# DSS_DSS_VIDL1_30202000h register map
Vendor: Texas Instruments
Peripheral module from a debugger description file (folder am62L).
Registers are 32-bit, read-write, reset 0x0 unless marked. A register's access mark holds for its fields unless they carry their own. Offsets are as the file gives them; lines under a group give offsets from that group; [hi:lo] are bit positions; {n}, {i} and the like mark numbered series; 'fields as' and 'values as' point back to an identical list; <NAME> marks a mode.

## DSS_VIDL1
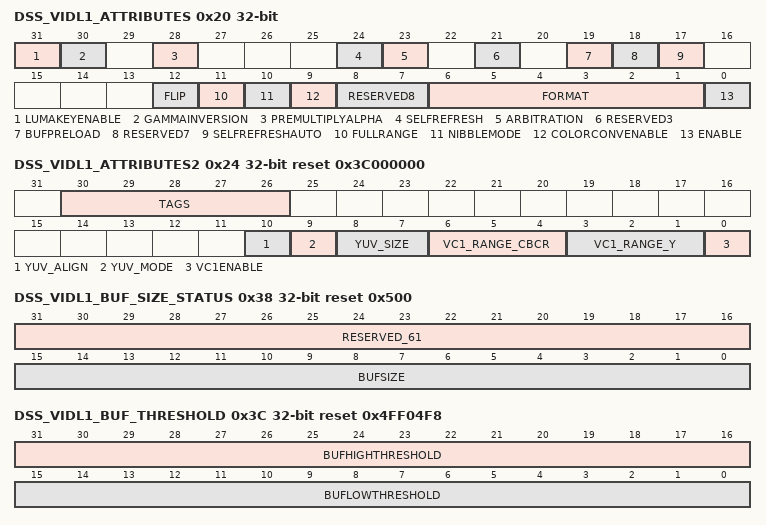
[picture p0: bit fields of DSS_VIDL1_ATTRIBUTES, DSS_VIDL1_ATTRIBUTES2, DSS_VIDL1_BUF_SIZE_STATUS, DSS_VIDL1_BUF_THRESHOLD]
0x20 DSS_VIDL1_ATTRIBUTES access per field — The register configures the attributes of the video window. Shadow register
  [31] LUMAKEYENABLE rw — Enable Luma Key transparency matching 0 Luma Key operation is disabled1 Luma Key operation is enabled
  [30] GAMMAINVERSION rw — Inverse Gamma support [using the CLUT table] 0 Gamma inversion is disabled1 Gamma inversion is enabled
  [28] PREMULTIPLYALPHA rw — The field configures the DISPC VID to process incoming data as premultiplied alpha data or non premultiplied alpha data. Default setting is non premultiplied alpha data 0 Non premultiplyalpha data color component1 Premultiplyalpha data color component
  [24] SELFREFRESH rw — Enables the self refresh of the video window, from its own DMA buffer only 0 The video pipeline accesses the interconnect to fetch data from the system memory1 The video pipeline does not need any more to fetch data from memory. Only the DMA buffer associated with the video1 is used. It takes effect after the frame has been loaded in the DMA buffer
  [23] ARBITRATION rw — Determines the priority of the video pipeline. The video pipeline is one of the high priority pipelines. The arbitration gives always the priority first to the high priority pipelines using round-robin between them. When there are only normal priority pipelines sending requests, the round-robin applies between the normal priority pipelines 0 The video pipeline is one of the normal priority pipelines1 The video pipeline is one of the high priority pipelines
  [21] RESERVED3 ro — Write 0's for future compatibility. Reads return 0
  [19] BUFPRELOAD rw — Video Preload Value 0 H/W prefetches pixels up to the preload value defined in the preload register1 H/W prefetches pixels up to high threshold value
  [18] RESERVED7 ro — Write 0's for future compatibility. Reads return 0
  [17] SELFREFRESHAUTO rw — Automatic self refresh mode 0 The transition from SELFREFRESH disabled to enabled is controlled SW1 The transition from SELFREFRESH disabled to enabled is controlled only by HW
  [12] FLIP rw — Describes the frame buffer flip operation 0 No Flip1 Frame Buffer is flipped
  [11] FULLRANGE rw — Color Space Conversion full range setting 0 Limited Range Selected1 Full Range Selected
  [10] NIBBLEMODE rw — Video Nibble mode [only for 1-, 2- and 4-bpp] 0 Nibble Mode Disabled1 Nibble Mode Enabled
  [9] COLORCONVENABLE rw — Enable the color space conversion. The HW does not enable/disable the conversion based on the pixel format 0 Color Space Conversion Disabled1 Color Space Conversion Enabled
  [8:7] RESERVED8 ro — Write 0's for future compatibility. Reads return 0
  [6:1] FORMAT rw — Video Format. It defines the pixel format when fetching the video frame buffer 0 Pixel format1 Pixel format2 Pixel format3 Pixel format4 Pixel format5 Pixel format6 Pixel format7 Pixel format8 Pixel format9 Pixel format10 Pixel format11 Pixel format12 Pixel format14 Pixel format15 Pixel format16 Pixel format17 Pixel format18 Pixel format19 Pixel format20 Pixel format21 Pixel format22 Pixel format23 Pixel format32 Pixel format33 Pixel format34 Pixel format37 Pixel format38 Pixel format39 Pixel format40 Pixel format41 Pixel format42 Pixel format46 Pixel format47 Pixel format48 Pixel format49 Pixel format61 Pixel format62 Pixel format63 Pixel format
  [0] ENABLE rw — Video pipeline Enable 0 Video Pipe Disabled1 Video Pipe Enabled
0x24 DSS_VIDL1_ATTRIBUTES2 reset 0x3C000000 — The register configures the attributes of the video window. Shadow register
  [30:26] TAGS — Number of OCP TAGS to be used for the pipeline [from 0x0 to 0xF]. A value of 0x0 means only a single tag will be used. A value of 0xF means all 16 tags can be used
  [10] YUV_ALIGN — Alignment [MSB or LSB align] for unpacked 10b/12b YUV data 0 lsb aligned - unused msb1 msb aligned - unused lsb
  [9] YUV_MODE — Mode of packing for YUV data [only for 10b/12b formats] 0 YUV 10-bit formats have the same component packing order as 8-bit formats except that the packing is done across a multiple 32-bit word with 2 MSB in each 32-bit word not used. YUV 12-bit formats have the same component packing order as 8-bit formats except that the packing is done across a multiple 64-bit word with 4 MSB in each 64-bit word not used1 YUV 10-bit/12-bit unpacked formats have the same component packing order as 8-bit formats except that each component is stored in a 16-bit container - with MSB or LSB bits within the 16-bit container not used depending on the MSB/LSB alignment
  [8:7] YUV_SIZE — Size of YUV data 8b/10b/12b 0 8b per component-default1 10b per component2 12b per component
  [6:4] VC1_RANGE_CBCR — Defines the VC1 range value for the CbCr component from 0 to 7
  [3:1] VC1_RANGE_Y — Defines the VC1 range value for the Y component from 0 to 7
  [0] VC1ENABLE — Enable/disable the VC1 range mapping processing. The bit-field is ignored if the format is not one of the supported YUV formats 0 VC1 range mapping disabled1 VC1 range mapping enabled
0x28 DSS_VIDL1_BA_0 — The register configures the base address of the single video buffer. In case of single plane ARGB or YUV, this is the BA. In case of two plane YUV, this is the BA_Y. In case of two plane RGB565-A8, this is the BA_Alpha. BA__0 & BA__1 for ping-pong mechanism with external trigger, based on the field polarity otherwise only BA__0 is used. Shadow register
  [31:0] BA — Video base address. Base address of the video buffer [Aligned on pixel size boundary except for the following. In case of RGB24 packed format, 4-pixel alignment is required. In case of YUV422, 2-pixel alignment is required. In case of YUV420, byte alignment is required]
0x2C DSS_VIDL1_BA_1 — The register configures the base address of the single video buffer. In case of single plane ARGB or YUV, this is the BA. In case of two plane YUV, this is the BA_Y. In case of two plane RGB565-A8, this is the BA_Alpha. BA__0 & BA__1 for ping-pong mechanism with external trigger, based on the field polarity otherwise only BA__0 is used. Shadow register
  fields as DSS_VIDL1_BA_0
0x30 DSS_VIDL1_BA_UV_0 — The register configures the base address of the UV buffer for two plane YUV or RGB buffer for two plane RGB565-A8, for the video window. BA_UV__0 & BA_UV__1 for ping-pong mechanism with external trigger, based on the field polarity otherwise only BA_UV__0 is used. Shadow register
  [31:0] BA — Video base address aligned on 16-bit boundary Base address of the UV video buffer used only in case of YUV420-NV12
0x34 DSS_VIDL1_BA_UV_1 — The register configures the base address of the UV buffer for two plane YUV or RGB buffer for two plane RGB565-A8, for the video window. BA_UV__0 & BA_UV__1 for ping-pong mechanism with external trigger, based on the field polarity otherwise only BA_UV__0 is used. Shadow register
  fields as DSS_VIDL1_BA_UV_0
0x38 DSS_VIDL1_BUF_SIZE_STATUS ro reset 0x500 — The register returns the Video buffer size for the video pipeline
  [31:16] RESERVED_61 — Write 0's for future compatibility Reads return 0
  [15:0] BUFSIZE — Video DMA buffer Size in number of 128-bits
0x3C DSS_VIDL1_BUF_THRESHOLD reset 0x4FF04F8 — The register configures the video buffer associated with the video pipeline. Shadow register
  [31:16] BUFHIGHTHRESHOLD — DMA buffer High Threshold. Number of 128-bits defining the threshold value
  [15:0] BUFLOWTHRESHOLD — DMA buffer Low Threshold. Number of 128-bits defining the threshold value
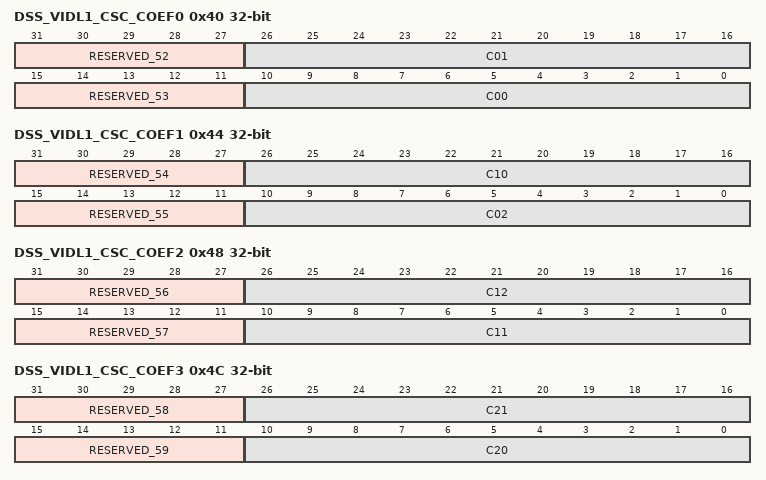
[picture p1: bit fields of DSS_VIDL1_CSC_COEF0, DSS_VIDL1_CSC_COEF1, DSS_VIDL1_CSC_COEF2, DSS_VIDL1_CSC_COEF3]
0x40 DSS_VIDL1_CSC_COEF0 access per field — The register configures the color space conversion matrix coefficients. Shadow register
  [31:27] RESERVED_52 ro — Write 0's for future compatibility Reads return 0
  [26:16] C01 rw — C01 Coefficient. Encoded signed value [from -1024 to 1023]
  [15:11] RESERVED_53 ro — Write 0's for future compatibility Reads return 0
  [10:0] C00 rw — C00 Coefficient. Encoded signed value [from -1024 to 1023]
0x44 DSS_VIDL1_CSC_COEF1 access per field — The register configures the color space conversion matrix coefficients. Shadow register
  [31:27] RESERVED_54 ro — Write 0's for future compatibility Reads return 0
  [26:16] C10 rw — C10 Coefficient. Encoded signed value [from -1024 to 1023]
  [15:11] RESERVED_55 ro — Write 0's for future compatibility Reads return 0
  [10:0] C02 rw — C02 Coefficient. Encoded signed value [from -1024 to 1023]
0x48 DSS_VIDL1_CSC_COEF2 access per field — The register configures the color space conversion matrix coefficients. Shadow register
  [31:27] RESERVED_56 ro — Write 0's for future compatibility Reads return 0
  [26:16] C12 rw — C12 Coefficient. Encoded signed value [from -1024 to 1023]
  [15:11] RESERVED_57 ro — Write 0's for future compatibility Reads return 0
  [10:0] C11 rw — C11 Coefficient. Encoded signed value [from -1024 to 1023]
0x4C DSS_VIDL1_CSC_COEF3 access per field — The register configures the color space conversion matrix coefficients. Shadow register
  [31:27] RESERVED_58 ro — Write 0's for future compatibility Reads return 0
  [26:16] C21 rw — C21 coefficient. Encoded signed value [from -1024 to 1023]
  [15:11] RESERVED_59 ro — Write 0's for future compatibility Reads return 0
  [10:0] C20 rw — C20 coefficient. Encoded signed value [from -1024 to 1023]
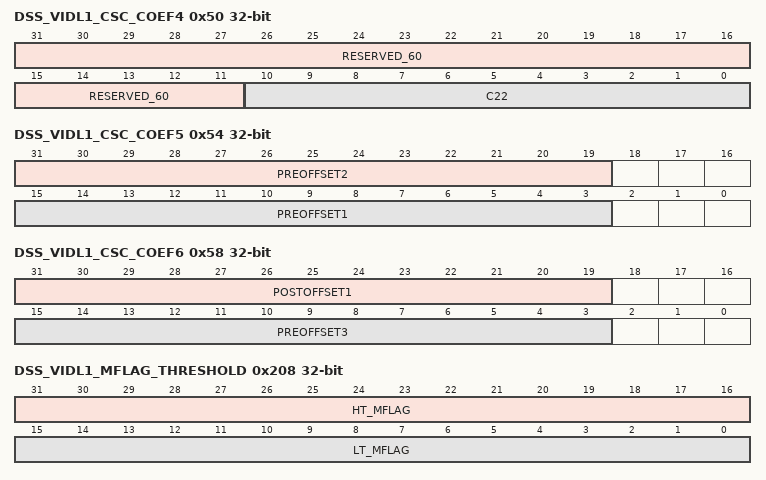
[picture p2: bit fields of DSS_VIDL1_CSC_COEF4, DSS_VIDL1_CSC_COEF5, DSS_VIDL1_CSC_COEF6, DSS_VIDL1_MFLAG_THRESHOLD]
0x50 DSS_VIDL1_CSC_COEF4 access per field — The register configures the color space conversion matrix coefficients. Shadow register
  [31:11] RESERVED_60 ro — Write 0's for future compatibility Reads return 0
  [10:0] C22 rw — C22 Coefficient. Encoded signed value [from -1024 to 1023]
0x54 DSS_VIDL1_CSC_COEF5 — The register configures the color space conversion matrix coefficients. Shadow register
  [31:19] PREOFFSET2 — Row-2 pre-offset. Encoded signed value [from -4096 to 4095]
  [15:3] PREOFFSET1 — Row1 pre-offset. Encoded signed value [from -4096 to 4095]
0x58 DSS_VIDL1_CSC_COEF6 — The register configures the color space conversion matrix coefficients. Shadow register
  [31:19] POSTOFFSET1 — Row-1 post-offset. Encoded signed value [from -4096 to 4095]
  [15:3] PREOFFSET3 — Row-3 pre-offset. Encoded signed value [from -4096 to 4095]
0x1FC DSS_VIDL1_GLOBAL_ALPHA reset 0xFF — The register defines the global alpha value for the video pipeline. Shadow register
  [7:0] GLOBALALPHA — Global alpha value from 0 to 255. 0 corresponds to fully transparent and 255 corresponds to fully opaque
0x208 DSS_VIDL1_MFLAG_THRESHOLD — MFLAG_THRESHOLD Register
  [31:16] HT_MFLAG — MFLAG High Threshold
  [15:0] LT_MFLAG — MFLAG Low Threshold
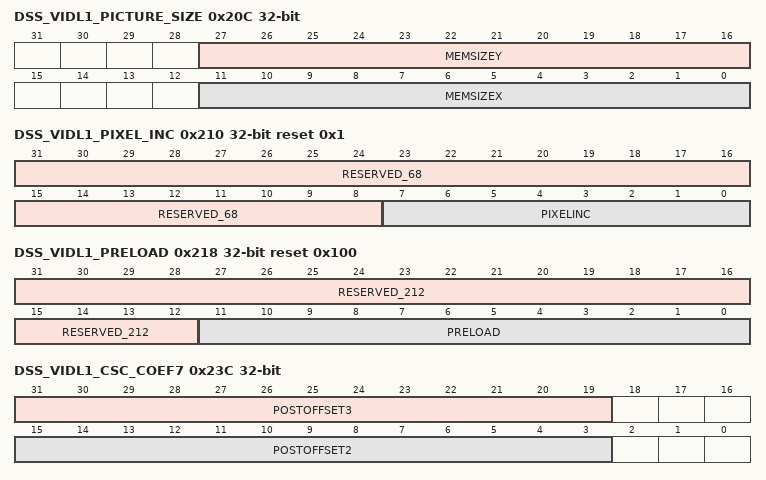
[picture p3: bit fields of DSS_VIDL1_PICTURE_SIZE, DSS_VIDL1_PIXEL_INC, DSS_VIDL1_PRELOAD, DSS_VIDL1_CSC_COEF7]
0x20C DSS_VIDL1_PICTURE_SIZE — The register configures the size of the video picture associated with the video layer before up/down-scaling. Shadow register
  [27:16] MEMSIZEY — Number of lines of the video picture Encoded value [from 1 to 4096] to specify the number of lines of the video picture in memory [program to value minus one]. When predecimation is set, the value represents the size of the image after predecimation but the max size of the unpredecimated image size in memory is still bounded to 2exp[11]
  [11:0] MEMSIZEX — Number of pixels of the video picture Encoded value [from 1 to 4096] to specify the number of pixels of the video picture in memory [program to value minus one]. The size is limited to the size of the line buffer of the vertical sampling block in case the video picture is processed by the vertical filtering unit [program to value minus one]. When predecimation is set, the value represents the size of the image after predecimation but the max size of the unpredecimated image size in memory is still bounded to 2exp[11]
0x210 DSS_VIDL1_PIXEL_INC access per field reset 0x1 — The register configures the number of bytes to increment between two pixels for the buffer associated with the video window. Shadow register
  [31:8] RESERVED_68 ro — Write 0's for future compatibility Reads return 0
  [7:0] PIXELINC rw — Number of bytes to increment between two pixels Encoded unsigned value [from 1 to 255] to specify the number of bytes between two pixels in the video buffer. The value 0 is invalid The value 1 means next pixel The value 1+n*bpp means increment of n pixels For YUV420. Max supported value is 128
0x218 DSS_VIDL1_PRELOAD access per field reset 0x100 — The register configures the DMA buffer of the video pipeline. Shadow register
  [31:12] RESERVED_212 ro — Write 0's for future compatibility Reads return 0
  [11:0] PRELOAD rw — DMA buffer preload value. Number of 128-bit words defining the preload value
0x21C DSS_VIDL1_ROW_INC reset 0x1 — The register configures the number of bytes to increment at the end of the row for the buffer associated with the video window. For YUV420 formats this corresponds to the Y Buffer. Shadow register
  [31:0] ROWINC — Number of bytes to increment at the end of the row Encoded signed value [from -2^31-1 to 2^31] to specify the number of bytes to increment at the end of the row in the video buffer. The value 0 is invalid. The value 1 means next pixel. The value 1+n*bpp means increment of n pixels The value 1- [n+1]*bpp means decrement of n pixels
0x22C DSS_VIDL1_BA_EXT_0 — The register configures the 16-bit base address extension. It is the base-address of the single video buffer for single plane ARGB or YUV. For the Y buffer for two plane YUV. For the Alpha buffer for two plane RGB565-A8. 0 & 1 : For ping-pong mechanism with external trigger, based on the field polarity. Shadow register
  [15:0] BA_EXT — Video base address extension [16 bits]. Addr extension to make the address space 48b wide
0x230 DSS_VIDL1_BA_EXT_1 — The register configures the 16-bit base address extension. It is the base-address of the single video buffer for single plane ARGB or YUV. For the Y buffer for two plane YUV. For the Alpha buffer for two plane RGB565-A8. 0 & 1 : For ping-pong mechanism with external trigger, based on the field polarity. Shadow register
  fields as DSS_VIDL1_BA_EXT_0
0x234 DSS_VIDL1_BA_UV_EXT_0 — The register configures the 16-bit base address extension of the UV buffer for two plane YUV or the RGB buffer for two plane RGB565-A8. 0 & 1 : For ping-pong mechanism with external trigger, based on the field polarity. Shadow register
  [15:0] BA_UV_EXT — Video base address extension [16 bits]. Addr extension to make the address space 48b wide
0x238 DSS_VIDL1_BA_UV_EXT_1 — The register configures the 16-bit base address extension of the UV buffer for two plane YUV or the RGB buffer for two plane RGB565-A8. 0 & 1 : For ping-pong mechanism with external trigger, based on the field polarity. Shadow register
  fields as DSS_VIDL1_BA_UV_EXT_0
0x23C DSS_VIDL1_CSC_COEF7 — The register configures the color space conversion matrix coefficients. Shadow register
  [31:19] POSTOFFSET3 — Row-3 post-offset. Encoded signed value [from -4096 to 4095]
  [15:3] POSTOFFSET2 — Row-2 post-offset. Encoded signed value [from -4096 to 4095]
0x248 DSS_VIDL1_ROW_INC_UV reset 0x1 — The register configures the number of bytes to increment at the end of the row for the UV buffer associated with the video window for YUV420 formats. For non-YUV420 formats this register is unused. Shadow register
  [31:0] ROWINC — Number of bytes to increment at the end of the row Encoded signed value [from -2^31-1 to 2^31] to specify the number of bytes to increment at the end of the row in the video buffer. The value 0 is invalid The value 1 means next pixel. The value 1+n*bpp means increment of n pixels. The value 1- [n+1]*bpp means decrement of n pixels
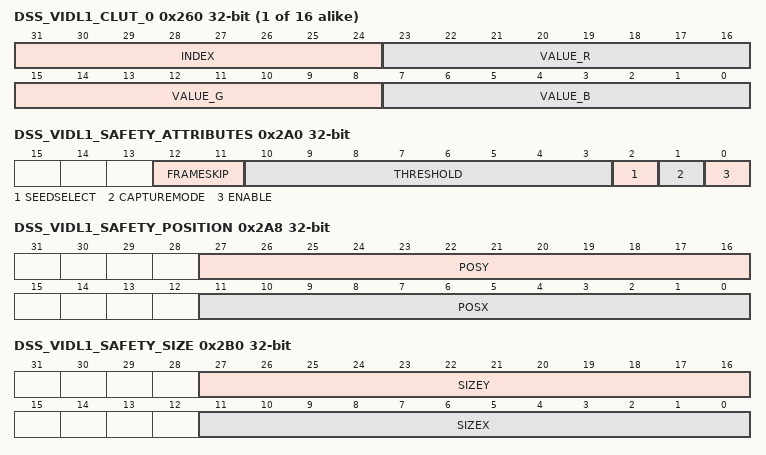
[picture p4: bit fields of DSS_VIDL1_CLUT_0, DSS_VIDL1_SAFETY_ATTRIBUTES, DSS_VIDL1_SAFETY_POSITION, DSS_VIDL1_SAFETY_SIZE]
{0x260+4i} DSS_VIDL1_CLUT_{i} wo (i=0..15) — The register configures the Color Look Up Table CLUT for VID pipeline. CLUT is used in conjunction with bitmap formats
  [31:24] INDEX — Defines the location in the table where the bit-fields VALUE_{R,G,B} is stored
  [23:16] VALUE_R — 8-bit R-value to store at the location in the table defined by the bit-field INDEX
  [15:8] VALUE_G — 8-bit G-value to store at the location in the table defined by the bit-field INDEX
  [7:0] VALUE_B — 8-bit B-value to store at the location in the table defined by the bit-field INDEX
0x2A0 DSS_VIDL1_SAFETY_ATTRIBUTES — The register configures the safety sub-region. Shadow register
  [12:11] FRAMESKIP — Indicates which frames to be skipped while doing FRAMEFREEZE or DATACHECK [Useful for interlaced displays]. 0x0: No frames are skipped, 0x1: Even Frames are skipped starting from second frame after ENABLE, 0x2: Odd Frames are skipped starting from first frame after ENABLE, 0x3: Reserved 0 No frames are skipped1 Even Frames are skipped starting from second frame after ENABLE2 Odd Frames are skipped starting from first frame after ENABLE3 Reserved
  [10:3] THRESHOLD — Allowed maximum number of frames with the same frame signature. When the freeze frame counter reaches 1 over this value [freeze_frame_thold+1], a freeze frame detection will occur. Note: The freeze frame counter is cleared on reset -OR- MISR not enabled -OR- terminal count reached -OR- compare == no match
  [2] SEEDSELECT — Initial seed selection control 0 Initial seed is always 0xFFFF_FFFF1 Initial seed is defined by SAFETY_LFSR_START.SEED
  [1] CAPTUREMODE — Mode of operation of the safety check module 0 Frame freeze detect enabled1 Data correctness check enabled
  [0] ENABLE — Safety check Enable for the region. Note: Transition from 0 to 1 clears the signature register
0x2A4 DSS_VIDL1_SAFETY_CAPT_SIGNATURE ro — The register captures the signature from the MISR of the safety sub-region. Shadow register
  [31:0] SIGNATURE — The register configures the reference signature of the safety sub-region. Shadow register
0x2A8 DSS_VIDL1_SAFETY_POSITION — The register configures the position of the safety sub-region. Shadow register
  [27:16] POSY — Y position of the safety sub-region. Encoded value [from 0 to 4095] to specify the Y position of the sub-region on the screen. The first line on the top of the screen has the Y-position 0
  [11:0] POSX — X position of the safety sub-region. Encoded value [from 0 to 4095] to specify the X position of the sub-region on the screen. The first pixel on the left of the screen has the X-position 0
0x2AC DSS_VIDL1_SAFETY_REF_SIGNATURE — The register configures the reference signature of the safety sub-region. Shadow register
0x2B0 DSS_VIDL1_SAFETY_SIZE — The register configures the size of the safety sub-region. Shadow register
  [27:16] SIZEY — Height of the safety sub-region. Encoded value [from 0 to 4095] to specify the height of the sub-region on the screen. One line height region has value of 0
  [11:0] SIZEX — Width of the safety sub-region. Encoded value [from 0 to 4095] to specify the width of the sub-region on the screen. One pixel wide region has value of 0
0x2B4 DSS_VIDL1_SAFETY_LFSR_SEED — The register configures the seed [initial value] of the MISR. Otherwise, the MISR is initialized with 0xFFFF_FFFF. Shadow register
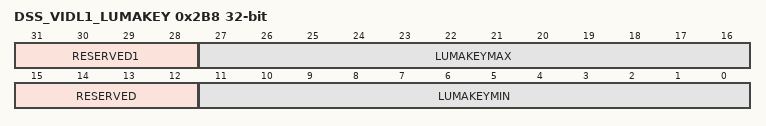
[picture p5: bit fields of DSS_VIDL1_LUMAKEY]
0x2B8 DSS_VIDL1_LUMAKEY access per field — The register configures the LUMA KEY transparency min and max values. Shadow register
  [31:28] RESERVED1 ro — Write 0's for future compatibility Reads return 0
  [27:16] LUMAKEYMAX rw — 12b luma_key_max value
  [15:12] RESERVED ro — Write 0's for future compatibility Reads return 0
  [11:0] LUMAKEYMIN rw — 12b luma_key_min value
